# G32M3101 register map
File version: 1.0
CPU: CM0+ r0p1, little endian, MPU, no FPU, 2 interrupt priority bits
Registers are 32-bit, read-write, reset 0x0 unless marked. A register's access mark holds for its fields unless they carry their own. Offsets are from the block's base; lines under a group give offsets from that group; [hi:lo] are bit positions; {n}, {i} and the like mark numbered series; 'fields as' and 'values as' point back to an identical list; <NAME> marks a mode.

## Memory map
0x40000000 ATMR size 0x400 — Advance timer
0x40001000 GTMR size 0x400 — General purpose timer
0x40002000 BTMR size 0x400 — Base timer
0x40003000 SPI size 0x400 — Serial peripheral interface
0x40004000 UART0 size 0x400 — Universal asynchronous receiver transmitter
0x40005000 UART1 size 0x400 — Universal asynchronous receiver transmitter
0x40006000 COMP size 0x400 — Comparator
0x40007000 WWDT size 0x400 — Window watchdog
0x40008000 IWDT size 0x400 — Independent watchdog
0x40009000 EINT size 0x400 — External interrupt/event controller
0x4000A000 LPTMR size 0x400 — Low-power timer
0x4000B000 ADC size 0x400 — Analog-to-digital converter
0x40020000 DMA size 0x400 — DMA controller
0x40020400 SCU size 0x400 — System configuration controller
0x40020800 FLASH size 0x400 — Flash memory controller
0x40020C00 CRC size 0x400 — Cryptographic processor
0x40021000 DIV size 0x400
0x40021400 GPIOA size 0x400 — General-purpose I/Os
0x40021800 GPIOB size 0x400 — General-purpose I/Os

## Interrupts
0 WWDT — Window Watchdog global interrupt
1 PVD (SCU) — PVD global interrupt
2 LVD (SCU) — PVD global interrupt
3 FLASH — FLASH global interrupt
4 RCM (SCU) — RCM global interrupt
5 EINT0_1 (EINT) — EINT Line 0 to 1 global interrupt
6 EINT2_3 (EINT) — EINT Line 2 to 3 global interrupt
7 EINT4_13 (EINT) — EINT Line 4 to 13 global interrupts
9 DMA_CH0 (DMA) — DMA_CH0 global interrupt
10 DMA_CH1 (DMA) — DMA_CH1 global interrupts
11 DMA_CH2 (DMA) — DMA_CH2 global interrupts
12 ADC — ADC global interrupt
13 ATMR_BRK_UP_TRG_COM (ATMR) — Atimer_BRK_UP_TRG_COM global interrupt
14 ATMR_CC (ATMR) — Atimer_CC global interrupt
15 GTMR — Gtimer interrupt
17 BTMR — Btimer global interrupt
19 LPTMR — LPtimer global interrupt
21 COMP0_1 (COMP) — COMP0 COMP1 global interrupt
25 SPI — SPI global interrupt
27 UART0 — UART0 global interrupt
28 UART1 — UART1 global interrupt

## GTMR — General purpose timer
Base 0x40001000
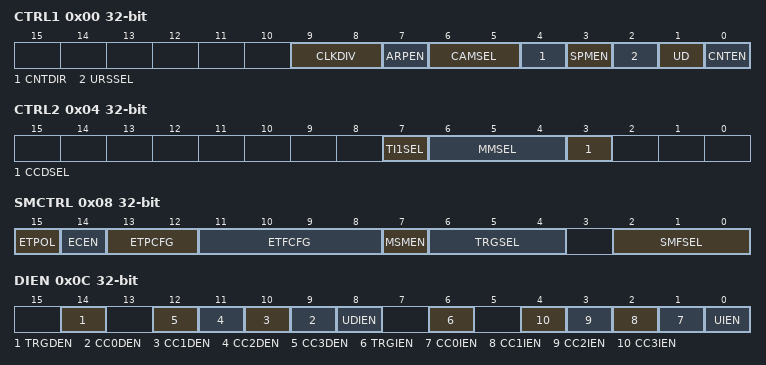
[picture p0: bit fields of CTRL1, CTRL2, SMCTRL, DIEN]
0x00 CTRL1 — control register 1
  [9:8] CLKDIV — Clock division
  [7] ARPEN — Auto-reload preload enable
  [6:5] CAMSEL — Center-aligned mode selection
  [4] CNTDIR — Direction
  [3] SPMEN — One-pulse mode
  [2] URSSEL — Update request source
  [1] UD — Update disable
  [0] CNTEN — Counter enable
0x04 CTRL2 — control register 2
  [7] TI1SEL — TI1 selection
  [6:4] MMSEL — Master mode selection
  [3] CCDSEL — Capture/compare DMA selection
0x08 SMCTRL — slave mode control register
  [15] ETPOL — External trigger polarity
  [14] ECEN — External clock enable
  [13:12] ETPCFG — External trigger prescaler
  [11:8] ETFCFG — External trigger filter
  [7] MSMEN — Master/Slave mode
  [6:4] TRGSEL — Trigger selection
  [2:0] SMFSEL — Slave mode selection
0x0C DIEN — DMA/Interrupt enable register
  [14] TRGDEN — Trigger DMA request enable
  [n+9] CC{n}DEN (n=0..3) — Capture/Compare {n} DMA request enable
  [8] UDIEN — Update DMA request enable
  [6] TRGIEN — Trigger interrupt enable
  [n+1] CC{n}IEN (n=0..3) — Capture/Compare {n} interrupt enable
  [0] UIEN — Update interrupt enable
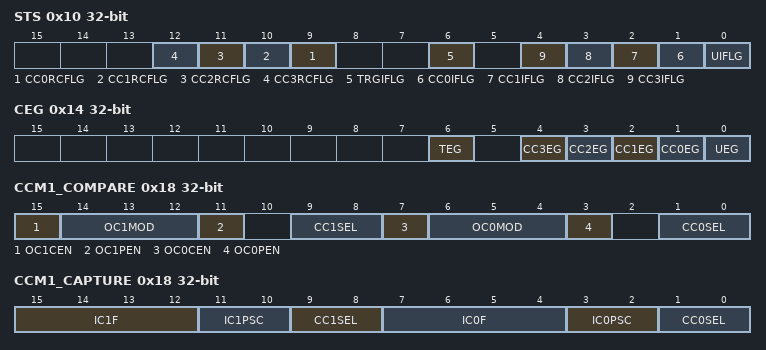
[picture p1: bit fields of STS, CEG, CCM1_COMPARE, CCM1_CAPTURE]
0x10 STS — status register
  [n+9] CC{n}RCFLG (n=0..3) — Capture/Compare {n} overcapture flag
  [6] TRGIFLG — Trigger interrupt flag
  [n+1] CC{n}IFLG (n=0..3) — Capture/compare {n} interrupt flag
  [0] UIFLG — Update interrupt flag
0x14 CEG wo — event generation register
  [6] TEG — Trigger generation
  [n+1] CC{n}EG (n=0..3) — Capture/compare {n} generation
  [0] UEG — Update generation
0x18 CCM1_COMPARE — capture/compare mode register 1 (output mode)
  [15] OC1CEN — Output Compare 1 clear enable
  [14:12] OC1MOD — Output Compare 1 mode
  [11] OC1PEN — Output Compare 1 preload enable
  [9:8] CC1SEL — Capture/Compare 1 selection
  [7] OC0CEN — Output Compare 0 clear enable
  [6:4] OC0MOD — Output Compare 0 mode
  [3] OC0PEN — Output Compare 0 preload enable
  [1:0] CC0SEL — Capture/Compare 0 selection
0x18 CCM1_CAPTURE (alternate view of CCM1_COMPARE) — capture/compare mode register 1 (input mode)
  [15:12] IC1F — Input capture 1 filter
  [11:10] IC1PSC — Input capture 1 prescaler
  [9:8] CC1SEL — Capture/Compare 1 selection
  [7:4] IC0F — Input capture 0 filter
  [3:2] IC0PSC — Input capture 0 prescaler
  [1:0] CC0SEL — Capture/Compare 0 selection
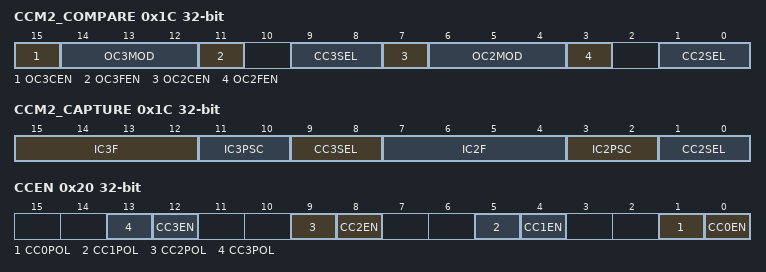
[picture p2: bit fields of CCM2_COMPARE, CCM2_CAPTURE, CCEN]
0x1C CCM2_COMPARE — capture/compare mode register 2 (output mode)
  [15] OC3CEN — Output compare 3 clear enable
  [14:12] OC3MOD — Output compare 3 mode
  [11] OC3FEN — Output compare 3 fast enable
  [9:8] CC3SEL — Capture/Compare 3 selection
  [7] OC2CEN — Output compare 2 clear enable
  [6:4] OC2MOD — Output compare 2 mode
  [3] OC2FEN — Output compare 2 fast enable
  [1:0] CC2SEL — Capture/Compare 2 selection
0x1C CCM2_CAPTURE (alternate view of CCM2_COMPARE) — capture/compare mode register 2 (input mode)
  [15:12] IC3F — Input capture 3 filter
  [11:10] IC3PSC — Input capture 3 prescaler
  [9:8] CC3SEL — Capture/compare 3 selection
  [7:4] IC2F — Input capture 2 filter
  [3:2] IC2PSC — Input capture 2 prescaler
  [1:0] CC2SEL — Capture/compare 2 selection
0x20 CCEN — capture/compare enable register
  [4n+1] CC{n}POL (n=0..3) — Capture/Compare {n} output Polarity
  [4n] CC{n}EN (n=0..3) — Capture/Compare {n} output enable
0x24 CNT — counter
  [31:0] CNT — Counter Value
0x28 PSC — prescaler
  [15:0] PSC — Prescaler value
0x2C AUTORLD reset 0xFFFFFFFF — auto-reload register
  [31:0] AUTORLD — Auto Reload Value
{0x34+4i} CC{i} (i=0..3) — capture/compare register {i}
  [31:0] CC{i} — Capture/Compare {i} value
